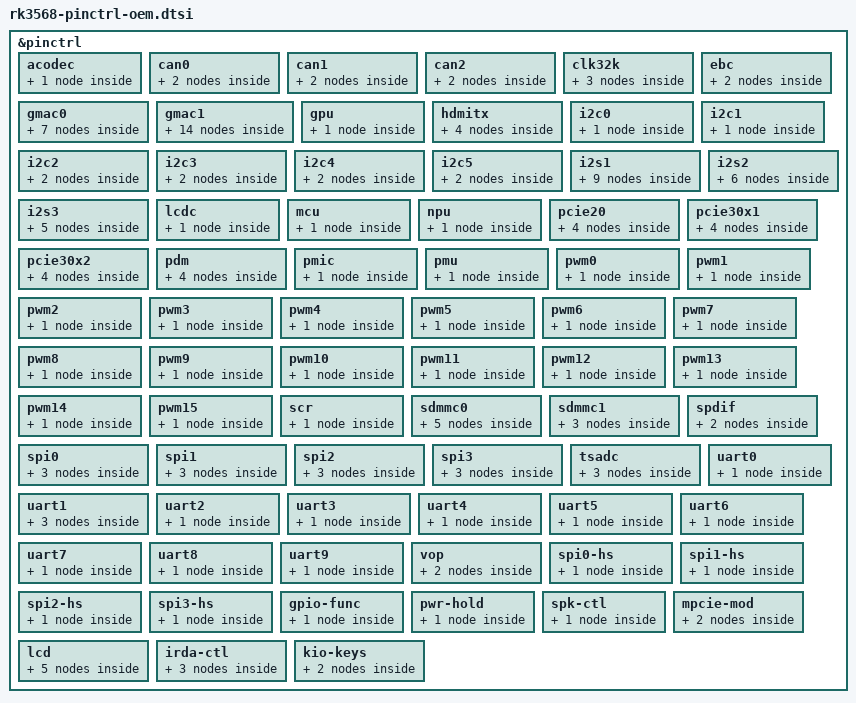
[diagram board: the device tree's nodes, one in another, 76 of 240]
// SPDX-License-Identifier: (GPL-2.0+ OR MIT)
/*
 * Copyright (c) 2020 Rockchip Electronics Co., Ltd.
 */

#include <dt-bindings/pinctrl/rockchip.h>
#include "rockchip-pinconf.dtsi"

/*
 * This file is auto generated by pin2dts tool, please keep these code
 * by adding changes at end of this file.
 */
&pinctrl {

	acodec {

		acodec_pins: acodec-pins {
			rockchip,pins = 
				<0x1 0x9 0x5 0x10e 
				0x1 0x1 0x5 0x10e 
				0x1 0x0 0x5 0x10e 
				0x1 0x7 0x5 0x10e 
				0x1 0x8 0x5 0x10e 
				0x1 0x3 0x5 0x10e 
				0x1 0x5 0x5 0x10e>;
			phandle = <0xd2>;
		};
	};

	can0 {
		/omit-if-no-ref/
		can0m0_pins: can0m0-pins {
			rockchip,pins =
				/* can0_rxm0 */
				<0 RK_PB4 2 &pcfg_pull_none>,
				/* can0_txm0 */
				<0 RK_PB3 2 &pcfg_pull_none>;
		};

		can0m1_pins: can0m1-pins {
			rockchip,pins = <0x2 0x2 0x4 0x10e 0x2 0x1 0x4 0x10e>;
			phandle = <0xd4>;
		};
	};

	can1 {
		/omit-if-no-ref/
		can1m0_pins: can1m0-pins {
			rockchip,pins =
				/* can1_rxm0 */
				<1 RK_PA0 3 &pcfg_pull_none>,
				/* can1_txm0 */
				<1 RK_PA1 3 &pcfg_pull_none>;
		};

		can1m1_pins: can1m1-pins {
			rockchip,pins = <0x4 0x12 0x3 0x10e 0x4 0x13 0x3 0x10e>;
			phandle = <0xd5>;
		};
	};

	can2 {

		can2m0_pins: can2m0-pins {
			rockchip,pins = <0x4 0xc 0x3 0x10e 0x4 0xd 0x3 0x10e>;
			phandle = <0xd6>;
		/omit-if-no-ref/
		can2m1_pins: can2m1-pins {
			rockchip,pins =
				/* can2_rxm1 */
				<2 RK_PB1 4 &pcfg_pull_none>,
				/* can2_txm1 */
				<2 RK_PB2 4 &pcfg_pull_none>;
		};

		};
	};

	clk32k {
		/omit-if-no-ref/
		clk32k_in: clk32k-in {
			rockchip,pins =
				/* clk32k_in */
				<0 RK_PB0 1 &pcfg_pull_none>;
		};

		clk32k_out0: clk32k-out0 {
			rockchip,pins = <0x0 0x8 0x2 0x10e>;
			phandle = <0x1e>;
		};

		/omit-if-no-ref/
		clk32k_out1: clk32k-out1 {
			rockchip,pins =
				/* clk32k_out1 */
				<2 RK_PC6 1 &pcfg_pull_none>;
		};
	};

	ebc {
		/omit-if-no-ref/
		ebc_extern: ebc-extern {
			rockchip,pins =
				/* ebc_sdce1 */
				<4 RK_PA7 2 &pcfg_pull_none>,
				/* ebc_sdce2 */
				<4 RK_PB0 2 &pcfg_pull_none>,
				/* ebc_sdce3 */
				<4 RK_PB1 2 &pcfg_pull_none>,
				/* ebc_sdshr */
				<4 RK_PB5 2 &pcfg_pull_none>,
				/* ebc_vcom */
				<4 RK_PB2 2 &pcfg_pull_none>;
		};

		ebc_pins: ebc-pins {
			rockchip,pins = <0x4 0x10 0x2 0x10e 0x4 0xb 0x2 0x10e 0x4 0xc 0x2 0x10e 0x4 0x6 0x2 0x10e 0x4 0x11 0x2 0x10e 0x3 0x16 0x2 0x10e 0x3 0x17 0x2 0x10e 0x3 0x18 0x2 0x10e 0x3 0x19 0x2 0x10e 0x3 0x1a 0x2 0x10e 0x3 0x1b 0x2 0x10e 0x3 0x1c 0x2 0x10e 0x3 0x1d 0x2 0x10e 0x3 0x1e 0x2 0x10e 0x3 0x1f 0x2 0x10e 0x4 0x0 0x2 0x10e 0x4 0x1 0x2 0x10e 0x4 0x2 0x2 0x10e 0x4 0x3 0x2 0x10e 0x4 0x4 0x2 0x10e 0x4 0x5 0x2 0x10e 0x4 0xe 0x2 0x10e 0x4 0xf 0x2 0x10e>;
			phandle = <0x6c>;
		};
	};

	gmac0 {

		gmac0_miim: gmac0-miim {
			rockchip,pins = <0x2 0x13 0x2 0x10e 0x2 0x14 0x2 0x10e>;
			phandle = <0xb6>;
		};

		/omit-if-no-ref/
		gmac0_clkinout: gmac0-clkinout {
			rockchip,pins =
				/* gmac0_mclkinout */
				<2 RK_PC2 2 &pcfg_pull_none>;
		};

		/omit-if-no-ref/
		gmac0_rx_er: gmac0-rx-er {
			rockchip,pins =
				/* gmac0_rxer */
				<2 RK_PC5 2 &pcfg_pull_none>;
		};

		/omit-if-no-ref/
		gmac0_rx_bus2: gmac0-rx-bus2 {
			rockchip,pins =
				/* gmac0_rxd0 */
				<2 RK_PB6 1 &pcfg_pull_none>,
				/* gmac0_rxd1 */
				<2 RK_PB7 2 &pcfg_pull_none>,
				/* gmac0_rxdvcrs */
				<2 RK_PC0 2 &pcfg_pull_none>;
		};

		/omit-if-no-ref/
		gmac0_tx_bus2: gmac0-tx-bus2 {
			rockchip,pins =
				/* gmac0_txd0 */
				<2 RK_PB3 1 &pcfg_pull_none_drv_level_2>,
				/* gmac0_txd1 */
				<2 RK_PB4 1 &pcfg_pull_none_drv_level_2>,
				/* gmac0_txen */
				<2 RK_PB5 1 &pcfg_pull_none>;
		};

		/omit-if-no-ref/
		gmac0_rgmii_clk: gmac0-rgmii-clk {
			rockchip,pins =
				/* gmac0_rxclk */
				<2 RK_PA5 2 &pcfg_pull_none>,
				/* gmac0_txclk */
				<2 RK_PB0 2 &pcfg_pull_none_drv_level_1>;
		};

		/omit-if-no-ref/
		gmac0_rgmii_bus: gmac0-rgmii-bus {
			rockchip,pins =
				/* gmac0_rxd2 */
				<2 RK_PA3 2 &pcfg_pull_none>,
				/* gmac0_rxd3 */
				<2 RK_PA4 2 &pcfg_pull_none>,
				/* gmac0_txd2 */
				<2 RK_PA6 2 &pcfg_pull_none_drv_level_2>,
				/* gmac0_txd3 */
				<2 RK_PA7 2 &pcfg_pull_none_drv_level_2>;
		};
	};

	gmac1 {
		/omit-if-no-ref/
		gmac1m0_miim: gmac1m0-miim {
			rockchip,pins =
				/* gmac1_mdcm0 */
				<3 RK_PC4 3 &pcfg_pull_none>,
				/* gmac1_mdiom0 */
				<3 RK_PC5 3 &pcfg_pull_none>;
		};

		/omit-if-no-ref/
		gmac1m0_clkinout: gmac1m0-clkinout {
			rockchip,pins =
				/* gmac1_mclkinoutm0 */
				<3 RK_PC0 3 &pcfg_pull_none>;
		};

		/omit-if-no-ref/
		gmac1m0_rx_er: gmac1m0-rx-er {
			rockchip,pins =
				/* gmac1_rxerm0 */
				<3 RK_PB4 3 &pcfg_pull_none>;
		};

		/omit-if-no-ref/
		gmac1m0_rx_bus2: gmac1m0-rx-bus2 {
			rockchip,pins =
				/* gmac1_rxd0m0 */
				<3 RK_PB1 3 &pcfg_pull_none>,
				/* gmac1_rxd1m0 */
				<3 RK_PB2 3 &pcfg_pull_none>,
				/* gmac1_rxdvcrsm0 */
				<3 RK_PB3 3 &pcfg_pull_none>;
		};

		/omit-if-no-ref/
		gmac1m0_tx_bus2: gmac1m0-tx-bus2 {
			rockchip,pins =
				/* gmac1_txd0m0 */
				<3 RK_PB5 3 &pcfg_pull_none_drv_level_2>,
				/* gmac1_txd1m0 */
				<3 RK_PB6 3 &pcfg_pull_none_drv_level_2>,
				/* gmac1_txenm0 */
				<3 RK_PB7 3 &pcfg_pull_none>;
		};

		/omit-if-no-ref/
		gmac1m0_rgmii_clk: gmac1m0-rgmii-clk {
			rockchip,pins =
				/* gmac1_rxclkm0 */
				<3 RK_PA7 3 &pcfg_pull_none>,
				/* gmac1_txclkm0 */
				<3 RK_PA6 3 &pcfg_pull_none_drv_level_1>;
		};

		/omit-if-no-ref/
		gmac1m0_rgmii_bus: gmac1m0-rgmii-bus {
			rockchip,pins =
				/* gmac1_rxd2m0 */
				<3 RK_PA4 3 &pcfg_pull_none>,
				/* gmac1_rxd3m0 */
				<3 RK_PA5 3 &pcfg_pull_none>,
				/* gmac1_txd2m0 */
				<3 RK_PA2 3 &pcfg_pull_none_drv_level_2>,
				/* gmac1_txd3m0 */
				<3 RK_PA3 3 &pcfg_pull_none_drv_level_2>;
		};

		gmac1m1_miim: gmac1m1-miim {
			rockchip,pins = <0x4 0xe 0x3 0x10e 0x4 0xf 0x3 0x10e>;
			phandle = <0x7e>;
		};

		/omit-if-no-ref/
		gmac1m1_clkinout: gmac1m1-clkinout {
			rockchip,pins =
				/* gmac1_mclkinoutm1 */
				<4 RK_PC1 3 &pcfg_pull_none>;
		};

		/omit-if-no-ref/
		gmac1m1_rx_er: gmac1m1-rx-er {
			rockchip,pins =
				/* gmac1_rxerm1 */
				<4 RK_PB2 3 &pcfg_pull_none>;
		};

		gmac1m1_rx_bus2: gmac1m1-rx-bus2 {
			rockchip,pins = <0x4 0x7 0x3 0x10e 0x4 0x8 0x3 0x10e 0x4 0x9 0x3 0x10e>;
			phandle = <0x80>;
		};

		gmac1m1_tx_bus2: gmac1m1-tx-bus2 {
			rockchip,pins = <0x4 0x4 0x3 0x111 0x4 0x5 0x3 0x111 0x4 0x6 0x3 0x10e>;
			phandle = <0x7f>;
		};

		gmac1m1_rgmii_clk: gmac1m1-rgmii-clk {
			rockchip,pins = <0x4 0x3 0x3 0x10e 0x4 0x0 0x3 0x112>;
			phandle = <0x81>;
		};

		gmac1m1_rgmii_bus: gmac1m1-rgmii-bus {
			rockchip,pins = <0x4 0x1 0x3 0x10e 0x4 0x2 0x3 0x10e 0x3 0x1e 0x3 0x111 0x3 0x1f 0x3 0x111>;
			phandle = <0x82>;
		};
	};

	gpu {
		/omit-if-no-ref/
		gpu_pins: gpu-pins {
			rockchip,pins =
				/* gpu_avs */
				<0 RK_PC0 2 &pcfg_pull_none>,
				/* gpu_pwren */
				<0 RK_PA6 4 &pcfg_pull_none>;
		};
	};

	hdmitx {

		hdmitxm0_cec: hdmitxm0-cec {
			rockchip,pins = <0x4 0x19 0x1 0x10e>;
			phandle = <0x9e>;
		};

		/omit-if-no-ref/
		hdmitxm1_cec: hdmitxm1-cec {
			rockchip,pins =
				/* hdmitxm1_cec */
				<0 RK_PC7 1 &pcfg_pull_none>;
		};

		hdmitx_scl: hdmitx-scl {
			rockchip,pins = <0x4 0x17 0x1 0x10e>;
			phandle = <0x9c>;
		};

		hdmitx_sda: hdmitx-sda {
			rockchip,pins = <0x4 0x18 0x1 0x10e>;
			phandle = <0x9d>;
		};
	};

	i2c0 {

		i2c0_xfer: i2c0-xfer {
			rockchip,pins = <0x0 0x9 0x1 0x113 0x0 0xa 0x1 0x113>;
			phandle = <0x34>;
		};
	};

	i2c1 {

		i2c1_xfer: i2c1-xfer {
			rockchip,pins = <0x0 0xb 0x1 0x113 0x0 0xc 0x1 0x113>;
			phandle = <0xd7>;
		};
	};

	i2c2 {

		i2c2m0_xfer: i2c2m0-xfer {
			rockchip,pins = <0x0 0xd 0x1 0x113 0x0 0xe 0x1 0x113>;
			phandle = <0xd8>;
		};

		/omit-if-no-ref/
		i2c2m1_xfer: i2c2m1-xfer {
			rockchip,pins =
				/* i2c2_sclm1 */
				<4 RK_PB5 1 &pcfg_pull_none_smt>,
				/* i2c2_sdam1 */
				<4 RK_PB4 1 &pcfg_pull_none_smt>;
		};
	};

	i2c3 {

		i2c3m0_xfer: i2c3m0-xfer {
			rockchip,pins = <0x1 0x1 0x1 0x113 0x1 0x0 0x1 0x113>;
			phandle = <0xd9>;
		};

		/omit-if-no-ref/
		i2c3m1_xfer: i2c3m1-xfer {
			rockchip,pins =
				/* i2c3_sclm1 */
				<3 RK_PB5 4 &pcfg_pull_none_smt>,
				/* i2c3_sdam1 */
				<3 RK_PB6 4 &pcfg_pull_none_smt>;
		};
	};

	i2c4 {

		i2c4m0_xfer: i2c4m0-xfer {
			rockchip,pins = <0x4 0xb 0x1 0x113 0x4 0xa 0x1 0x113>;
			phandle = <0xda>;
		};

		/omit-if-no-ref/
		i2c4m1_xfer: i2c4m1-xfer {
			rockchip,pins =
				/* i2c4_sclm1 */
				<2 RK_PB2 2 &pcfg_pull_none_smt>,
				/* i2c4_sdam1 */
				<2 RK_PB1 2 &pcfg_pull_none_smt>;
		};
	};

	i2c5 {

		i2c5m0_xfer: i2c5m0-xfer {
			rockchip,pins = <0x3 0xb 0x4 0x113 0x3 0xc 0x4 0x113>;
			phandle = <0xdb>;
		};

		/omit-if-no-ref/
		i2c5m1_xfer: i2c5m1-xfer {
			rockchip,pins =
				/* i2c5_sclm1 */
				<4 RK_PC7 2 &pcfg_pull_none_smt>,
				/* i2c5_sdam1 */
				<4 RK_PD0 2 &pcfg_pull_none_smt>;
		};
	};

	i2s1 {
		/omit-if-no-ref/
		i2s1m0_lrckrx: i2s1m0-lrckrx {
			rockchip,pins =
				/* i2s1m0_lrckrx */
				<1 RK_PA6 1 &pcfg_pull_none>;
		};

		i2s1m0_lrcktx: i2s1m0-lrcktx {
			rockchip,pins = <0x1 0x5 0x1 0x10e>;
			phandle = <0xc3>;
		};

		i2s1m0_mclk: i2s1m0-mclk {
			rockchip,pins = <0x1 0x2 0x1 0x10e>;
			phandle = <0x3e>;
		};

		/omit-if-no-ref/
		i2s1m0_sclkrx: i2s1m0-sclkrx {
			rockchip,pins =
				/* i2s1m0_sclkrx */
				<1 RK_PA4 1 &pcfg_pull_none>;
		};

		i2s1m0_sclktx: i2s1m0-sclktx {
			rockchip,pins = <0x1 0x3 0x1 0x10e>;
			phandle = <0xc2>;
		};

		i2s1m0_sdi0: i2s1m0-sdi0 {
			rockchip,pins = <0x1 0xb 0x1 0x10e>;
			phandle = <0xc4>;
		};

		/omit-if-no-ref/
		i2s1m0_sdi1: i2s1m0-sdi1 {
			rockchip,pins =
				/* i2s1m0_sdi1 */
				<1 RK_PB2 2 &pcfg_pull_none>;
		};

		i2s1m0_sdo0: i2s1m0-sdo0 {
			rockchip,pins = <0x1 0x7 0x1 0x10e>;
			phandle = <0xc5>;
		};

		/omit-if-no-ref/
		i2s1m0_sdo1: i2s1m0-sdo1 {
			rockchip,pins =
				/* i2s1m0_sdo1 */
				<1 RK_PB0 1 &pcfg_pull_none>;
		};

	};

	i2s2 {
		/omit-if-no-ref/
		i2s2m0_lrckrx: i2s2m0-lrckrx {
			rockchip,pins =
				/* i2s2m0_lrckrx */
				<2 RK_PC0 1 &pcfg_pull_none>;
		};

		i2s2m0_lrcktx: i2s2m0-lrcktx {
			rockchip,pins = <0x2 0x13 0x1 0x10e>;
			phandle = <0xc7>;
		};

		/omit-if-no-ref/
		i2s2m0_sclkrx: i2s2m0-sclkrx {
			rockchip,pins =
				/* i2s2m0_sclkrx */
				<2 RK_PB7 1 &pcfg_pull_none>;
		};

		i2s2m0_sclktx: i2s2m0-sclktx {
			rockchip,pins = <0x2 0x12 0x1 0x10e>;
			phandle = <0xc6>;
		};

		i2s2m0_sdi: i2s2m0-sdi {
			rockchip,pins = <0x2 0x15 0x1 0x10e>;
			phandle = <0xc8>;
		};

		i2s2m0_sdo: i2s2m0-sdo {
			rockchip,pins = <0x2 0x14 0x1 0x10e>;
			phandle = <0xc9>;
		};
	};

	i2s3 {

		i2s3m0_lrck: i2s3m0-lrck {
			rockchip,pins = <0x3 0x4 0x4 0x10e>;
			phandle = <0xcb>;
		};

		/omit-if-no-ref/
		i2s3m0_mclk: i2s3m0-mclk {
			rockchip,pins =
				/* i2s3m0_mclk */
				<3 RK_PA2 4 &pcfg_pull_none>;
		};
		i2s3m0_sclk: i2s3m0-sclk {
			rockchip,pins = <0x3 0x3 0x4 0x10e>;
			phandle = <0xca>;
		};

		i2s3m0_sdi: i2s3m0-sdi {
			rockchip,pins = <0x3 0x6 0x4 0x10e>;
			phandle = <0xcc>;
		};

		i2s3m0_sdo: i2s3m0-sdo {
			rockchip,pins = <0x3 0x5 0x4 0x10e>;
			phandle = <0xcd>;
		};
	};

	lcdc {

		lcdc_ctl: lcdc-ctl {
			rockchip,pins = <0x3 0x0 0x1 0x10e 0x2 0x18 0x1 0x10e 0x2 0x19 0x1 0x10e 0x2 0x1a 0x1 0x10e 0x2 0x1b 0x1 0x10e 0x2 0x1c 0x1 0x10e 0x2 0x1d 0x1 0x10e 0x2 0x1e 0x1 0x10e 0x2 0x1f 0x1 0x10e 0x3 0x1 0x1 0x10e 0x3 0x2 0x1 0x10e 0x3 0x3 0x1 0x10e 0x3 0x4 0x1 0x10e 0x3 0x5 0x1 0x10e 0x3 0x6 0x1 0x10e 0x3 0x7 0x1 0x10e 0x3 0x8 0x1 0x10e 0x3 0x9 0x1 0x10e 0x3 0xa 0x1 0x10e 0x3 0xb 0x1 0x10e 0x3 0xc 0x1 0x10e 0x3 0xd 0x1 0x10e 0x3 0xe 0x1 0x10e 0x3 0xf 0x1 0x10e 0x3 0x10 0x1 0x10e 0x3 0x13 0x1 0x10e 0x3 0x11 0x1 0x10e 0x3 0x12 0x1 0x10e>;
			phandle = <0x30>;
		};
	};

	mcu {
		/omit-if-no-ref/
		mcu_pins: mcu-pins {
			rockchip,pins =
				/* mcu_jtagtck */
				<0 RK_PB4 4 &pcfg_pull_none>,
				/* mcu_jtagtdi */
				<0 RK_PC1 4 &pcfg_pull_none>,
				/* mcu_jtagtdo */
				<0 RK_PB3 4 &pcfg_pull_none>,
				/* mcu_jtagtms */
				<0 RK_PC2 4 &pcfg_pull_none>,
				/* mcu_jtagtrstn */
				<0 RK_PC3 4 &pcfg_pull_none>;
		};
	};

	npu {
		/omit-if-no-ref/
		npu_pins: npu-pins {
			rockchip,pins =
				/* npu_avs */
				<0 RK_PC1 2 &pcfg_pull_none>;
		};
	};

	pcie20 {
		/omit-if-no-ref/
		pcie20m0_pins: pcie20m0-pins {
			rockchip,pins =
				/* pcie20_clkreqnm0 */
				<0 RK_PA5 3 &pcfg_pull_none>,
				/* pcie20_perstnm0 */
				<0 RK_PB6 3 &pcfg_pull_none>,
				/* pcie20_wakenm0 */
				<0 RK_PB5 3 &pcfg_pull_none>;
		};

		/omit-if-no-ref/
		pcie20m1_pins: pcie20m1-pins {
			rockchip,pins =
				/* pcie20_clkreqnm1 */
				<2 RK_PD0 4 &pcfg_pull_none>,
				/* pcie20_perstnm1 */
				<3 RK_PC1 4 &pcfg_pull_none>,
				/* pcie20_wakenm1 */
				<2 RK_PD1 4 &pcfg_pull_none>;
		};

		/omit-if-no-ref/
		pcie20m2_pins: pcie20m2-pins {
			rockchip,pins =
				/* pcie20_clkreqnm2 */
				<1 RK_PB0 4 &pcfg_pull_none>,
				/* pcie20_perstnm2 */
				<1 RK_PB2 4 &pcfg_pull_none>,
				/* pcie20_wakenm2 */
				<1 RK_PB1 4 &pcfg_pull_none>;
		};

		/omit-if-no-ref/
		pcie20_buttonrstn: pcie20-buttonrstn {
			rockchip,pins =
				/* pcie20_buttonrstn */
				<0 RK_PB4 3 &pcfg_pull_none>;
		};
	};

	pcie30x1 {
		/omit-if-no-ref/
		pcie30x1m0_pins: pcie30x1m0-pins {
			rockchip,pins =
				/* pcie30x1_clkreqnm0 */
				<0 RK_PA4 3 &pcfg_pull_none>,
				/* pcie30x1_perstnm0 */
				<0 RK_PC3 3 &pcfg_pull_none>,
				/* pcie30x1_wakenm0 */
				<0 RK_PC2 3 &pcfg_pull_none>;
		};

		/omit-if-no-ref/
		pcie30x1m1_pins: pcie30x1m1-pins {
			rockchip,pins =
				/* pcie30x1_clkreqnm1 */
				<2 RK_PD2 4 &pcfg_pull_none>,
				/* pcie30x1_perstnm1 */
				<3 RK_PA1 4 &pcfg_pull_none>,
				/* pcie30x1_wakenm1 */
				<2 RK_PD3 4 &pcfg_pull_none>;
		};

		/omit-if-no-ref/
		pcie30x1m2_pins: pcie30x1m2-pins {
			rockchip,pins =
				/* pcie30x1_clkreqnm2 */
				<1 RK_PA5 4 &pcfg_pull_none>,
				/* pcie30x1_perstnm2 */
				<1 RK_PA2 4 &pcfg_pull_none>,
				/* pcie30x1_wakenm2 */
				<1 RK_PA3 4 &pcfg_pull_none>;
		};

		/omit-if-no-ref/
		pcie30x1_buttonrstn: pcie30x1-buttonrstn {
			rockchip,pins =
				/* pcie30x1_buttonrstn */
				<0 RK_PB3 3 &pcfg_pull_none>;
		};
	};

	pcie30x2 {
		/omit-if-no-ref/
		pcie30x2m0_pins: pcie30x2m0-pins {
			rockchip,pins =
				/* pcie30x2_clkreqnm0 */
				<0 RK_PA6 2 &pcfg_pull_none>,
				/* pcie30x2_perstnm0 */
				<0 RK_PC6 3 &pcfg_pull_none>,
				/* pcie30x2_wakenm0 */
				<0 RK_PC5 3 &pcfg_pull_none>;
		};

		/omit-if-no-ref/
		pcie30x2m1_pins: pcie30x2m1-pins {
			rockchip,pins =
				/* pcie30x2_clkreqnm1 */
				<2 RK_PD4 4 &pcfg_pull_none>,
				/* pcie30x2_perstnm1 */
				<2 RK_PD6 4 &pcfg_pull_none>,
				/* pcie30x2_wakenm1 */
				<2 RK_PD5 4 &pcfg_pull_none>;
		};

		/omit-if-no-ref/
		pcie30x2m2_pins: pcie30x2m2-pins {
			rockchip,pins =
				/* pcie30x2_clkreqnm2 */
				<4 RK_PC2 4 &pcfg_pull_none>,
				/* pcie30x2_perstnm2 */
				<4 RK_PC4 4 &pcfg_pull_none>,
				/* pcie30x2_wakenm2 */
				<4 RK_PC3 4 &pcfg_pull_none>;
		};

		/omit-if-no-ref/
		pcie30x2_buttonrstn: pcie30x2-buttonrstn {
			rockchip,pins =
				/* pcie30x2_buttonrstn */
				<0 RK_PB0 3 &pcfg_pull_none>;
		};
	};

	pdm {
		/omit-if-no-ref/
		pdmm0_clk: pdmm0-clk {
			rockchip,pins =
				/* pdm_clk0m0 */
				<1 RK_PA6 3 &pcfg_pull_none>;
		};

		pdmm0_clk1: pdmm0-clk1 {
			rockchip,pins = <0x1 0x4 0x3 0x10e>;
			phandle = <0xce>;
		};

		/omit-if-no-ref/
		pdmm0_sdi0: pdmm0-sdi0 {
			rockchip,pins =
				/* pdmm0_sdi0 */
				<1 RK_PB3 2 &pcfg_pull_none>;
		};

		pdmm0_sdi1: pdmm0-sdi1 {
			rockchip,pins = <0x1 0xa 0x3 0x10e>;
			phandle = <0xcf>;
		};
	};

	pmic {
		/omit-if-no-ref/
		pmic_pins: pmic-pins {
			rockchip,pins =
				/* pmic_sleep */
				<0 RK_PA2 1 &pcfg_pull_none>;
		};
	};

	pmu {
		/omit-if-no-ref/
		pmu_pins: pmu-pins {
			rockchip,pins =
				/* pmu_debug0 */
				<0 RK_PA5 4 &pcfg_pull_none>,
				/* pmu_debug1 */
				<0 RK_PA6 3 &pcfg_pull_none>,
				/* pmu_debug2 */
				<0 RK_PC4 4 &pcfg_pull_none>,
				/* pmu_debug3 */
				<0 RK_PC5 4 &pcfg_pull_none>,
				/* pmu_debug4 */
				<0 RK_PC6 4 &pcfg_pull_none>,
				/* pmu_debug5 */
				<0 RK_PC7 4 &pcfg_pull_none>;
		};
	};

	pwm0 {

		pwm0m0_pins: pwm0m0-pins {
			rockchip,pins = <0x0 0xf 0x1 0x10e>;
			phandle = <0x42>;
		};
	};

	pwm1 {

		pwm1m0_pins: pwm1m0-pins {
			rockchip,pins = <0x0 0x10 0x1 0x10e>;
			phandle = <0x43>;
		};
	};

	pwm2 {

		pwm2m0_pins: pwm2m0-pins {
			rockchip,pins = <0x0 0x11 0x1 0x10e>;
			phandle = <0x44>;
		};
	};

	pwm3 {

		pwm3_pins: pwm3-pins {
			rockchip,pins = <0x0 0x12 0x1 0x10e>;
			phandle = <0x45>;
		};
	};

	pwm4 {

		pwm4_pins: pwm4-pins {
			rockchip,pins = <0x0 0x13 0x1 0x10e>;
			phandle = <0xf6>;
		};
	};

	pwm5 {

		pwm5_pins: pwm5-pins {
			rockchip,pins = <0x0 0x14 0x1 0x10e>;
			phandle = <0xf7>;
		};
	};

	pwm6 {

		pwm6_pins: pwm6-pins {
			rockchip,pins = <0x0 0x15 0x1 0x10e>;
			phandle = <0xf8>;
		};
	};

	pwm7 {

		pwm7_pins: pwm7-pins {
			rockchip,pins = <0x0 0x16 0x1 0x10e>;
			phandle = <0xf9>;
		};
	};

	pwm8 {

		pwm8m0_pins: pwm8m0-pins {
			rockchip,pins = <0x3 0x9 0x5 0x10e>;
			phandle = <0xfa>;
		};
	};

	pwm9 {

		pwm9m0_pins: pwm9m0-pins {
			rockchip,pins = <0x3 0xa 0x5 0x10e>;
			phandle = <0xfb>;
		};
	};

	pwm10 {

		pwm10m0_pins: pwm10m0-pins {
			rockchip,pins = <0x3 0xd 0x5 0x10e>;
			phandle = <0xfc>;
		};
	};

	pwm11 {

		pwm11m0_pins: pwm11m0-pins {
			rockchip,pins = <0x3 0xe 0x5 0x10e>;
			phandle = <0xfd>;
		};
	};

	pwm12 {

		pwm12m0_pins: pwm12m0-pins {
			rockchip,pins = <0x3 0xf 0x2 0x10e>;
			phandle = <0xfe>;
		};
	};

	pwm13 {

		pwm13m0_pins: pwm13m0-pins {
			rockchip,pins = <0x3 0x10 0x2 0x10e>;
			phandle = <0xff>;
		};
	};

	pwm14 {

		pwm14m0_pins: pwm14m0-pins {
			rockchip,pins = <0x3 0x14 0x1 0x10e>;
			phandle = <0x100>;
		};
	};

	pwm15 {

		pwm15m0_pins: pwm15m0-pins {
			rockchip,pins = <0x3 0x15 0x1 0x10e>;
			phandle = <0x101>;
		};
	};

	scr {

		scr_pins: scr-pins {
			rockchip,pins = <0x1 0x2 0x3 0x10e 0x1 0x7 0x3 0x110 0x1 0x3 0x3 0x110 0x1 0x5 0x3 0x10e>;
			phandle = <0xd3>;
		};
	};

	sdmmc0 {

		sdmmc0_bus4: sdmmc0-bus4 {
			rockchip,pins = <0x1 0x1d 0x1 0x10f 0x1 0x1e 0x1 0x10f 0x1 0x1f 0x1 0x10f 0x2 0x0 0x1 0x10f>;
			phandle = <0xb9>;
		};

		sdmmc0_clk: sdmmc0-clk {
			rockchip,pins = <0x2 0x2 0x1 0x10f>;
			phandle = <0xba>;
		};

		sdmmc0_cmd: sdmmc0-cmd {
			rockchip,pins = <0x2 0x1 0x1 0x10f>;
			phandle = <0xbb>;
		};

		sdmmc0_det: sdmmc0-det {
			rockchip,pins = <0x0 0x4 0x1 0x110>;
			phandle = <0xbc>;
		};

		/omit-if-no-ref/
		sdmmc0_pwren: sdmmc0-pwren {
			rockchip,pins =
				/* sdmmc0_pwren */
				<0 RK_PA5 1 &pcfg_pull_none>;
		};
	};

	sdmmc1 {

		sdmmc1_bus4: sdmmc1-bus4 {
			rockchip,pins = <0x2 0x3 0x1 0x10f 0x2 0x4 0x1 0x10f 0x2 0x5 0x1 0x10f 0x2 0x6 0x1 0x10f>;
			phandle = <0xbe>;
		};

		sdmmc1_clk: sdmmc1-clk {
			rockchip,pins = <0x2 0x8 0x1 0x10f>;
			phandle = <0xc0>;
		};

		sdmmc1_cmd: sdmmc1-cmd {
			rockchip,pins = <0x2 0x7 0x1 0x10f>;
			phandle = <0xbf>;
		};
	};

	spdif {

		spdifm0_tx: spdifm0-tx {
			rockchip,pins = <0x1 0x4 0x4 0x10e>;
			phandle = <0xd1>;
		};

		/omit-if-no-ref/
		spdifm1_tx: spdifm1-tx {
			rockchip,pins =
				/* spdifm1_tx */
				<3 RK_PC5 2 &pcfg_pull_none>;
		};
	};

	spi0 {

		spi0m0_pins: spi0m0-pins {
			rockchip,pins = <0x0 0xd 0x2 0x10e 0x0 0x15 0x2 0x10e 0x0 0xe 0x2 0x10e>;
			phandle = <0xde>;
		};

		spi0m0_cs0: spi0m0-cs0 {
			rockchip,pins = <0x0 0x16 0x2 0x10e>;
			phandle = <0xdc>;
		};

		spi0m0_cs1: spi0m0-cs1 {
			rockchip,pins = <0x0 0x14 0x2 0x10e>;
			phandle = <0xdd>;
		};
	};

	spi1 {

		spi1m0_pins: spi1m0-pins {
			rockchip,pins = <0x2 0xd 0x3 0x10e 0x2 0xe 0x3 0x10e 0x2 0xf 0x4 0x10e>;
			phandle = <0xe2>;
		};

		spi1m0_cs0: spi1m0-cs0 {
			rockchip,pins = <0x2 0x10 0x4 0x10e>;
			phandle = <0xe0>;
		};

		spi1m0_cs1: spi1m0-cs1 {
			rockchip,pins = <0x2 0x16 0x3 0x10e>;
			phandle = <0xe1>;
		};
	};

	spi2 {

		spi2m0_pins: spi2m0-pins {
			rockchip,pins = <0x2 0x11 0x4 0x10e 0x2 0x12 0x4 0x10e 0x2 0x13 0x4 0x10e>;
			phandle = <0xe6>;
		};

		spi2m0_cs0: spi2m0-cs0 {
			rockchip,pins = <0x2 0x14 0x4 0x10e>;
			phandle = <0xe4>;
		};

		spi2m0_cs1: spi2m0-cs1 {
			rockchip,pins = <0x2 0x15 0x4 0x10e>;
			phandle = <0xe5>;
		};
	};

	spi3 {

		spi3m0_pins: spi3m0-pins {
			rockchip,pins = <0x4 0xb 0x4 0x10e 0x4 0x8 0x4 0x10e 0x4 0xa 0x4 0x10e>;
			phandle = <0xea>;
		};

		spi3m0_cs0: spi3m0-cs0 {
			rockchip,pins = <0x4 0x6 0x4 0x10e>;
			phandle = <0xe8>;
		};

		spi3m0_cs1: spi3m0-cs1 {
			rockchip,pins = <0x4 0x7 0x4 0x10e>;
			phandle = <0xe9>;
		};
	};

	tsadc {
		/omit-if-no-ref/
		tsadcm0_shut: tsadcm0-shut {
			rockchip,pins =
				/* tsadcm0_shut */
				<0 RK_PA1 1 &pcfg_pull_none>;
		};

		/omit-if-no-ref/
		tsadcm1_shut: tsadcm1-shut {
			rockchip,pins =
				/* tsadcm1_shut */
				<0 RK_PA2 2 &pcfg_pull_none>;
		};

		tsadc_shutorg: tsadc-shutorg {
			rockchip,pins = <0x0 0x1 0x2 0x10e>;
			phandle = <0x103>;
		};
	};

	uart0 {

		uart0_xfer: uart0-xfer {
			rockchip,pins = <0x0 0x10 0x3 0x110 0x0 0x11 0x3 0x110>;
			phandle = <0x41>;
		};
	};

	uart1 {

		uart1m0_xfer: uart1m0-xfer {
			rockchip,pins = <0x2 0xb 0x2 0x110 0x2 0xc 0x2 0x110>;
			phandle = <0xec>;
		};

		uart1m0_ctsn: uart1m0-ctsn {
			rockchip,pins = <0x2 0xe 0x2 0x10e>;
			phandle = <0xed>;
		};

		uart1m0_rtsn: uart1m0-rtsn {
			rockchip,pins = <0x2 0xd 0x2 0x10e>;
			phandle = <0x12e>;
		};
	};

	uart2 {

		uart2m0_xfer: uart2m0-xfer {
			rockchip,pins = <0x0 0x18 0x1 0x110 0x0 0x19 0x1 0x110>;
			phandle = <0xee>;
		};
	};

	uart3 {

		uart3m1_xfer: uart3m1-xfer {
			rockchip,pins = <0x3 0x10 0x4 0x110 0x3 0xf 0x4 0x110>;
			phandle = <0xef>;
		};
	};

	uart4 {

		uart4m1_xfer: uart4m1-xfer {
			rockchip,pins = <0x3 0x9 0x4 0x110 0x3 0xa 0x4 0x110>;
			phandle = <0xf0>;
		};
	};

	uart5 {

		uart5m1_xfer: uart5m1-xfer {
			rockchip,pins = <0x3 0x13 0x4 0x110 0x3 0x12 0x4 0x110>;
			phandle = <0xf1>;
		};
	};

	uart6 {

		uart6m1_xfer: uart6m1-xfer {
			rockchip,pins = <0x1 0x1e 0x3 0x110 0x1 0x1d 0x3 0x110>;
			phandle = <0xf2>;
		};
	};

	uart7 {

		uart7m1_xfer: uart7m1-xfer {
			rockchip,pins = <0x3 0x15 0x4 0x110 0x3 0x14 0x4 0x110>;
			phandle = <0xf3>;
		};
	};

	uart8 {

		uart8m1_xfer: uart8m1-xfer {
			rockchip,pins = <0x3 0x0 0x4 0x110 0x2 0x1f 0x4 0x110>;
			phandle = <0xf4>;
		};
	};

	uart9 {

		uart9m1_xfer: uart9m1-xfer {
			rockchip,pins = <0x4 0x16 0x4 0x110 0x4 0x15 0x4 0x110>;
			phandle = <0xf5>;
		};
	};

	vop {
		/omit-if-no-ref/
		vopm0_pins: vopm0-pins {
			rockchip,pins =
				/* vop_pwmm0 */
				<0 RK_PC3 2 &pcfg_pull_none>;
		};

		/omit-if-no-ref/
		vopm1_pins: vopm1-pins {
			rockchip,pins =
				/* vop_pwmm1 */
				<3 RK_PC4 2 &pcfg_pull_none>;
		};
	};

	spi0-hs {

		spi0m0_pins_hs: spi0m0-pins {
			rockchip,pins = <0x0 0xd 0x2 0x115 0x0 0x15 0x2 0x115 0x0 0xe 0x2 0x115>;
			phandle = <0xdf>;
		};
	};

	spi1-hs {

		spi1m0_pins_hs: spi1m0-pins {
			rockchip,pins = <0x2 0xd 0x3 0x115 0x2 0xe 0x3 0x115 0x2 0xf 0x4 0x115>;
			phandle = <0xe3>;
		};
	};

	spi2-hs {

		spi2m0_pins_hs: spi2m0-pins {
			rockchip,pins = <0x2 0x11 0x4 0x115 0x2 0x12 0x4 0x115 0x2 0x13 0x4 0x115>;
			phandle = <0xe7>;
		};
	};

	spi3-hs {

		spi3m0_pins_hs: spi3m0-pins {
			rockchip,pins = <0x4 0xb 0x4 0x115 0x4 0x8 0x4 0x115 0x4 0xa 0x4 0x115>;
			phandle = <0xeb>;
		};
	};

	gpio-func {

		tsadc_gpio_func: tsadc-gpio-func {
			rockchip,pins = <0x0 0x1 0x0 0x10e>;
			phandle = <0x102>;
		};
	};

	pwr-hold {

		hold_gpio: hold-gpio {
			rockchip,pins = <0x3 0x11 0x0 0x10e>;
			phandle = <0x130>;
		};
	};

	spk-ctl {

		spk_ctl_h: spk-ctl-h {
			rockchip,pins = <0x1 0x8 0x0 0x10e>;
			phandle = <0x3f>;
		};
	};

	mpcie-mod {

		mpcie-pwr-en {
			rockchip,pins = <0x0 0x1d 0x0 0x10e>;
			phandle = <0x1e4>;
		};

		mpcie-rst-l {
			rockchip,pins = <0x0 0x1e 0x0 0x10e>;
			phandle = <0x1e5>;
		};
	};

	lcd {

		lcd_bl_en: lcd-bl-en {
			rockchip,pins = <0x3 0x1 0x0 0x10e>;
			phandle = <0x11d>;
		};

		lcd_bl2_en: lcd-bl2-en {
			rockchip,pins = <0x2 0x1d 0x0 0x10e>;
			phandle = <0x11f>;
		};

		vcc_lvds_en: vcc-lvds-en {
			rockchip,pins = <0x1 0x18 0x0 0x10e>;
			phandle = <0x12a>;
		};

		dsi0_cvt_en: dsi0-cvt-en {
			rockchip,pins = <0x3 0x8 0x0 0x10e>;
			phandle = <0x94>;
		};

		dsi0_cvt_rst: dsi0-cvt-rst {
			rockchip,pins = <0x3 0x7 0x0 0x10e>;
			phandle = <0x95>;
		};
	};

	irda-ctl {

		irda_rem: irda-rem {
			rockchip,pins = <0x0 0x12 0x0 0x10e>;
			phandle = <0x132>;
		};

		irda_led: irda-led {
			rockchip,pins = <0x3 0x1c 0x0 0x10e>;
			phandle = <0x133>;
		};

		irda_ion: irda-ion {
			rockchip,pins = <0x3 0x1d 0x0 0x117>;
			phandle = <0x134>;
		};
	};

	kio-keys {

		kio2d0-pull {
			rockchip,pins = <0x2 0x18 0x0 0x110>;
			phandle = <0x119>;
		};

		kio3d3-pull {
			rockchip,pins = <0x2 0x1b 0x0 0x110>;
			phandle = <0x11a>;
		};
	};

};
